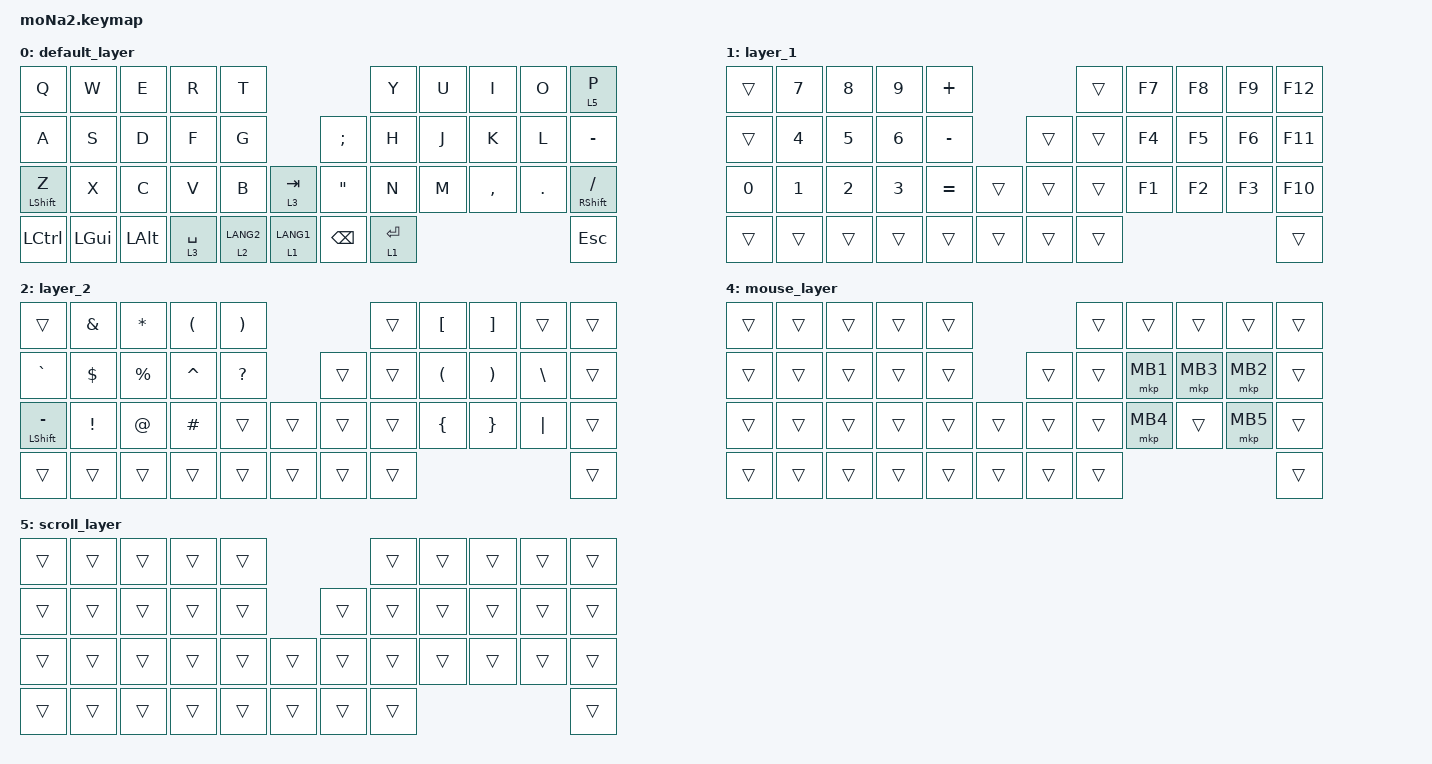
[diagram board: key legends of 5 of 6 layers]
/* moNa2.keymap — US論理 + layout-shift（kpオーバーライド）対応 完全版
 * 方針：
 *  - US配列でIME切替は LANG/HANZEN を使わず、常に “生の backtick” (`) を送る
 *  - そのため layout-shift を一時OFF→GRAVE→ON する &grave_raw マクロを使用
 *  - Keymap Editor上はUS配列のまま視覚一致（&kp を上書き）
 */
/* 重要：kpオーバーライドは他インクルードより“下”に置く */

#include <layout_shift_kp_override.dtsi>
#include <behaviors.dtsi>
#include <dt-bindings/zmk/bt.h>
#include <dt-bindings/zmk/keys.h>
#include <dt-bindings/zmk/pointing.h>

#define ZMK_POINTING_DEFAULT_SCRL_VAL 100
#define MOUSE 4
#define SCROLL 5

&mt {
    flavor = "balanced";
    quick-tap-ms = <0>;
};

/ {
    /* ===== Macros ===== */

    macros {
        /* OS/配列を確実に揃えるため、トグルではなく明示ON/OFFを使う */

        pc_mode: pc_mode {
            compatible = "zmk,behavior-macro";
            label = "PC_MODE";
            #binding-cells = <0>;

            /* Windows: BTプロファイル0 + レイアウトシフト ON + PC用レイヤへ */

            bindings = <&bt BT_SEL 0 &tog_ls_on &to 0>;
        };

        iphone_mode: iphone_mode {
            compatible = "zmk,behavior-macro";
            label = "IPHONE_MODE";
            #binding-cells = <0>;

            /* iPhone: 例としてBT1 + レイアウトシフト OFF + iOS用レイヤへ */

            bindings = <&bt BT_SEL 1 &tog_ls_off &to 0>;
        };

        ipad_mode_2: ipad_mode_2 {
            compatible = "zmk,behavior-macro";
            label = "IPAD_MODE_2";
            #binding-cells = <0>;

            /* iPad: BT2 + レイアウトシフト OFF + iOS用レイヤへ */

            bindings = <&bt BT_SEL 2 &tog_ls_off &to 0>;
        };

        /* IME切替用：layout-shift を一時OFF→GRAVE→ON（常に“生の`”を送る） */

        grave_raw: grave_raw {
            compatible = "zmk,behavior-macro";
            label = "GRAVE_RAW";
            #binding-cells = <0>;
            bindings = <&tog_ls_off &kp GRAVE &tog_ls_on>;
        };

        /* 汎用：任意のレイヤへ戻る（既存のまま） */

        to_layer_0: to_layer_0 {
            compatible = "zmk,behavior-macro-one-param";
            label = "TO_LAYER_0";
            #binding-cells = <1>;
            bindings = <&to 0 &macro_param_1to1 &kp MACRO_PLACEHOLDER>;
        };
    };

    /* ===== Custom Behaviors ===== */

    behaviors {
        lt_to_layer_0: lt_to_layer_0 {
            compatible = "zmk,behavior-hold-tap";
            label = "LAYER_TAP_TO_0";
            bindings = <&mo>, <&to_layer_0>;

            #binding-cells = <2>;
            tapping-term-ms = <200>;
        };

        /* マウスホイール回転 */

        scroll_up_down: behavior_sensor_rotate_mouse_wheel_up_down {
            compatible = "zmk,behavior-sensor-rotate";
            #sensor-binding-cells = <0>;
            bindings = <&msc SCRL_UP>, <&msc SCRL_DOWN>;

            tap-ms = <20>;
        };
    };

    /* ===== Keymap ===== */

    keymap {
        compatible = "zmk,keymap";

        /* --- PC Layer 0: Default（US論理） --- */

        default_layer {
            bindings = <
&kp Q             &kp W     &kp E         &kp R        &kp T                                          &kp Y        &kp U  &kp I      &kp O    &lt 5 P
&kp A             &kp S     &kp D         &kp F        &kp G                       &kp SEMICOLON      &kp H        &kp J  &kp K      &kp L    &kp MINUS
&mt LEFT_SHIFT Z  &kp X     &kp C         &kp V        &kp B        &lt 3 TAB      &kp DOUBLE_QUOTES  &kp N        &kp M  &kp COMMA  &kp DOT  &mt RIGHT_SHIFT SLASH
&kp LCTRL         &kp LGUI  &kp LEFT_ALT  &lt 3 SPACE  &lt 2 LANG2  &lt 1 LANG1    &kp BACKSPACE      &lt 1 ENTER                             &kp ESC
            >;

            sensor-bindings =
                <&scroll_up_down>,
                <&inc_dec_kp C_VOL_DN C_VOL_UP>;
        };

        /* --- PC Layer 1: Numbers / Function keys ---
         */

        layer_1 {
            bindings = <
&trans  &kp N7  &kp N8  &kp N9  &kp PLUS                     &trans  &kp F7  &kp F8  &kp F9  &kp F12
&trans  &kp N4  &kp N5  &kp N6  &kp MINUS            &trans  &trans  &kp F4  &kp F5  &kp F6  &kp F11
&kp N0  &kp N1  &kp N2  &kp N3  &kp EQUAL  &trans    &trans  &trans  &kp F1  &kp F2  &kp F3  &kp F10
&trans  &trans  &trans  &trans  &trans     &trans    &trans  &trans                          &trans
            >;

            sensor-bindings = <&scroll_up_down>;
        };

        /* --- PC Layer 2: Navigation --- */

        layer_2 {
            bindings = <
&trans                &kp AMPERSAND    &kp ASTERISK  &kp LEFT_PARENTHESIS  &kp RIGHT_PARENTHESIS                    &trans  &kp LEFT_BRACKET      &kp RIGHT_BRACKET      &trans         &trans
&kp GRAVE             &kp DOLLAR       &kp PERCENT   &kp CARET             &kp QUESTION                     &trans  &trans  &kp LEFT_PARENTHESIS  &kp RIGHT_PARENTHESIS  &kp BACKSLASH  &trans
&mt LEFT_SHIFT MINUS  &kp EXCLAMATION  &kp AT        &kp HASH              &trans                 &trans    &trans  &trans  &kp LEFT_BRACE        &kp RIGHT_BRACE        &kp PIPE       &trans
&trans                &trans           &trans        &trans                &trans                 &trans    &trans  &trans                                                              &trans
            >;
        };

        /* --- Layer 3: Navigation --- */

        navigation {
            bindings = <
&trans  &trans  &trans  &trans  &trans                    &kp PG_UP  &trans          &kp UP_ARROW    &trans           &kp PG_DN
&trans  &kp LG(LS(S))  &trans  &trans  &trans            &trans  &kp HOME  &kp LEFT_ARROW  &kp DOWN_ARROW  &kp RIGHT_ARROW  &kp END          &trans
&trans     &trans          &trans          &trans           &trans     &trans    &trans  &trans  &trans  &trans  &trans  &trans
&trans     &trans          &trans          &trans           &trans     &trans    &trans  &trans                          &trans
            >;
        };

        /* --- iPad/iPhone Layer 4: Default（US論理） --- */
        /* --- iPad/iPhone Layer 5: Symbols（US論理） --- */
        /* --- iPad/iPhone Layer 6: Navigation --- */
        /* --- Layer 7: Auto Mouse --- */

        mouse_layer {
            bindings = <
&trans  &trans  &trans  &trans  &trans                    &trans  &trans    &trans    &trans    &trans
&trans  &trans  &trans  &trans  &trans            &trans  &trans  &mkp MB1  &mkp MB3  &mkp MB2  &trans
&trans  &trans  &trans  &trans  &trans  &trans    &trans  &trans  &mkp MB4  &trans    &mkp MB5  &trans
&trans  &trans  &trans  &trans  &trans  &trans    &trans  &trans                                &trans
            >;
        };

        scroll_layer {
            bindings = <
&trans  &trans  &trans  &trans  &trans                    &trans  &trans  &trans  &trans  &trans
&trans  &trans  &trans  &trans  &trans            &trans  &trans  &trans  &trans  &trans  &trans
&trans  &trans  &trans  &trans  &trans  &trans    &trans  &trans  &trans  &trans  &trans  &trans
&trans  &trans  &trans  &trans  &trans  &trans    &trans  &trans                          &trans
            >;

            sensor-bindings = <&scroll_up_down>;
        };
    };
};
